# LM3S6965 register map
Vendor: Texas Instruments; File version: 0.1.0
CPU: Cortex-M3 r2p2, little endian, MPU, no FPU, VTOR, 3 interrupt priority bits
Registers are 32-bit, read-write, no defined reset value unless marked. A register's access mark holds for its fields unless they carry their own. Offsets are from the block's base; [hi:lo] are bit positions; {n}, {i} and the like mark numbered series.

## UART0 — Universal asynchronous receiver/transmitter 0.
Base 0x4000C000
Same registers: UART1 0x4000D000
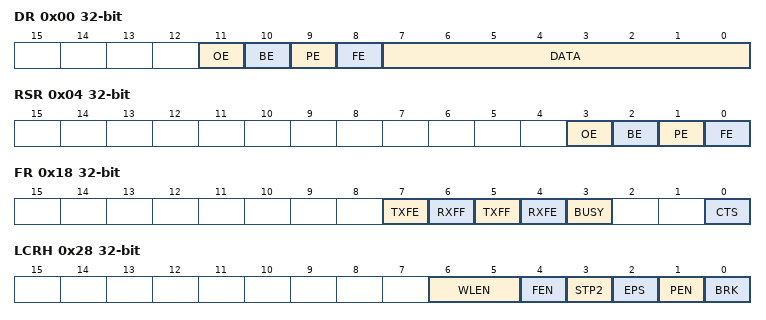
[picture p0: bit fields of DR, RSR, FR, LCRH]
0x00 DR — UART Data
  [11] OE ro — Overrun error.
  [10] BE ro — Break error.
  [9] PE ro — Parity error.
  [8] FE ro — Framing error.
  [7:0] DATA — Transmit/receive data.
0x04 RSR — UART receive status register view.
  [3] OE ro — Overrun error status.
  [2] BE ro — Break error status.
  [1] PE ro — Parity error status.
  [0] FE ro — Framing error status.
0x04 ECR (alternate view of RSR) — UART error clear register view.
  [3:0] ERROR wo — Writing clears receive status errors.
0x18 FR — UART Flag
  [7] TXFE ro — Transmit FIFO empty.
  [6] RXFF ro — Receive FIFO full.
  [5] TXFF ro — Transmit FIFO full.
  [4] RXFE ro — Receive FIFO empty.
  [3] BUSY ro — UART busy transmitting.
  [0] CTS ro — Clear to send state.
0x1C ILPR — UART IrDA Low-Power Register
0x20 IBRD — UART Integer Baud-Rate Divisor
  [15:0] DIVINT — Integer baud divisor.
0x24 FBRD — UART Fractional Baud-Rate Divisor
  [5:0] DIVFRAC — Fractional baud divisor.
0x28 LCRH — UART Line Control
  [6:5] WLEN — Word length.
    {v}={v+5}-bit data (v=0..3)
  [4] FEN — FIFO enable.
  [3] STP2 — Two stop bits.
  [2] EPS — Even parity select.
  [1] PEN — Parity enable.
  [0] BRK — Send break.
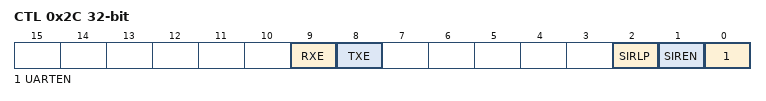
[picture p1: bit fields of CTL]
0x2C CTL — UART Control
  [9] RXE — Receive enable.
  [8] TXE — Transmit enable.
  [2] SIRLP — IrDA low-power mode.
  [1] SIREN — IrDA enable.
  [0] UARTEN — UART enable.
0x30 IFLS — UART Interrupt FIFO Level Select
0x34 IM — UART Interrupt Mask
0x38 RIS — UART Raw Interrupt Status
0x3C MIS — UART Masked Interrupt Status
0x40 ICR wo — UART Interrupt Clear

## I2C0 — Inter-integrated circuit controller 0 with master and slave sub-blocks.
Base 0x40020000
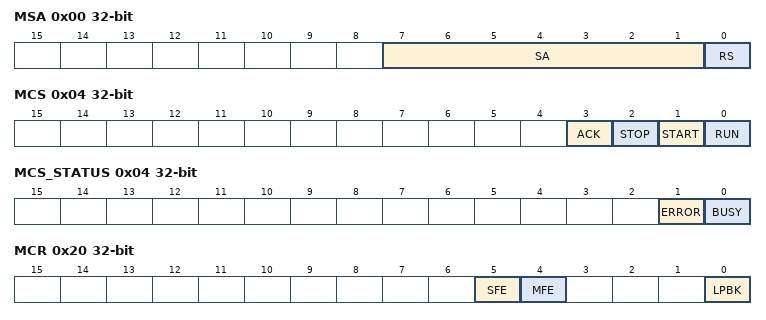
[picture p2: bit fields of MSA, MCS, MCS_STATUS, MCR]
0x00 MSA — I2C Master Slave Address
  [7:1] SA — Target slave address.
  [0] RS — Receive/not-send indicator.
0x04 MCS — I2C Master Control register view.
  [3] ACK — Acknowledge control.
  [2] STOP — Generate STOP condition.
  [1] START — Generate START condition.
  [0] RUN — Start I2C master operation.
0x04 MCS_STATUS (alternate view of MCS) — I2C Master Status register readback view.
  [1] ERROR ro — Error status on readback.
  [0] BUSY ro — Master busy status on readback.
0x08 MDR — I2C Master Data
  [7:0] DATA — Master transmit/receive data.
0x0C MTPR — I2C Master Timer Period
0x10 MIMR — I2C Master Interrupt Mask
0x14 MRIS — I2C Master Raw Interrupt Status
0x18 MMIS — I2C Master Masked Interrupt Status
0x1C MICR wo — I2C Master Interrupt Clear
0x20 MCR — I2C Master Configuration
  [5] SFE — Slave function enable.
  [4] MFE — Master function enable.
  [0] LPBK — Loopback enable.
0x800 SOAR — I2C Slave Own Address
  [6:0] OAR — Slave own address.
0x804 SCSR — I2C Slave Control/Status
0x808 SDR — I2C Slave Data
  [7:0] DATA — Slave data.
0x80C SIMR — I2C Slave Interrupt Mask
0x810 SRIS — I2C Slave Raw Interrupt Status
0x814 SMIS — I2C Slave Masked Interrupt Status
0x818 SICR wo — I2C Slave Interrupt Clear

## TIMER0 — General-purpose timer module 0 with Timer A and Timer B halves.
Base 0x40030000
Same registers: TIMER1 0x40031000, TIMER2 0x40032000, TIMER3 0x40033000
0x00 CFG — GPTM Configuration
  [2:0] CFG — GPTM configuration.
    0=full-32-bit (32-bit timer configuration); 1=rtc (32-bit RTC configuration); 4=split-16-bit (Two 16-bit timers configuration)
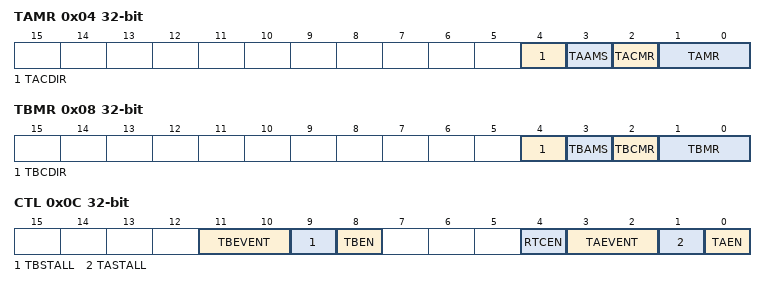
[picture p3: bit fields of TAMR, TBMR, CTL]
0x04 TAMR — GPTM Timer A Mode
  [4] TACDIR — Count direction.
  [3] TAAMS — Alternate mode select for PWM.
  [2] TACMR — Capture mode select.
  [1:0] TAMR — Timer A mode.
    1=One-shot mode; 2=Periodic mode; 3=Capture mode
0x08 TBMR — GPTM Timer B Mode
  [4] TBCDIR — Count direction.
  [3] TBAMS — Alternate mode select for PWM.
  [2] TBCMR — Capture mode select.
  [1:0] TBMR — Timer B mode.
    1=One-shot mode; 2=Periodic mode; 3=Capture mode
0x0C CTL — GPTM Control
  [11:10] TBEVENT — Timer B event selection.
  [9] TBSTALL — Timer B stall in debug.
  [8] TBEN — Timer B enable.
  [4] RTCEN — RTC enable.
  [3:2] TAEVENT — Timer A event selection.
  [1] TASTALL — Timer A stall in debug.
  [0] TAEN — Timer A enable.
0x18 IMR — GPTM Interrupt Mask
0x1C RIS — GPTM Raw Interrupt Status
0x20 MIS — GPTM Masked Interrupt Status
0x24 ICR wo — GPTM Interrupt Clear
0x28 TAILR — GPTM Timer A Interval Load
0x2C TBILR — GPTM Timer B Interval Load
0x30 TAMATCHR — GPTM Timer A Match
0x34 TBMATCHR — GPTM Timer B Match
0x38 TAPR — GPTM Timer A Prescale
0x3C TBPR — GPTM Timer B Prescale
0x40 TAPMR — GPTM TimerA Prescale Match
0x44 TBPMR — GPTM TimerB Prescale Match
0x48 TAR — GPTM Timer A
0x4C TBR — GPTM Timer B

## FLASH_CTRL — Flash memory control block.
Base 0x400FD000
0x00 FMA — Flash Memory Address
0x04 FMD — Flash Memory Data
0x08 FMC — Flash Memory Control
0x0C FCRIS — Flash Controller Raw Interrupt Status
0x10 FCIM — Flash Controller Interrupt Mask
0x14 FCMISC — Flash Controller Masked Interrupt Status and Clear
{0x1200+4i} FMPRE{i} (i=0..3) — Flash Memory Protection Read Enable {i}
{0x1400+4i} FMPPE{i} (i=0..3) — Flash Memory Protection Program Enable {i}

## SYSCTL — System control block for clocks, resets, device capabilities, and reset causes.
Base 0x400FE000
0x00 DID0 — Device Identification 0
0x04 DID1 — Device Identification 1
{0x8+4i} DC{i} (i=0..4) — Device Capabilities {i}
0x2C PBORCTL — Brown-Out Reset Control
0x30 LDOPCTL — LDO Power Control
0x3C SRCR0 — Software Reset Control 0
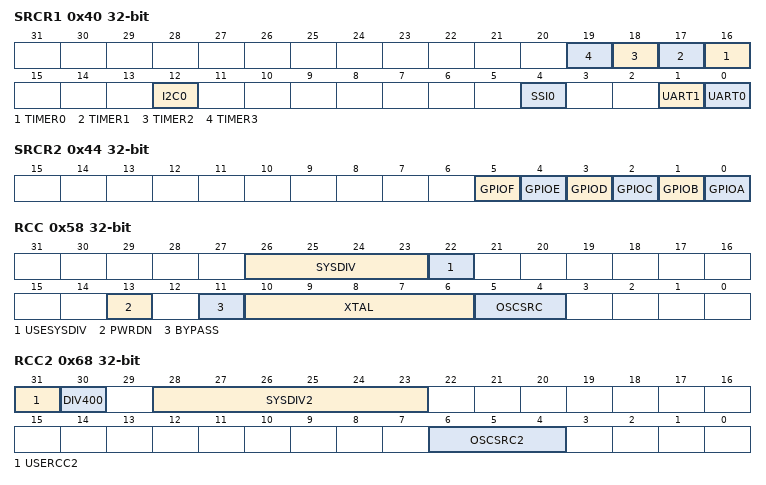
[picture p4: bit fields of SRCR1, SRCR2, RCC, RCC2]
0x40 SRCR1 — Software Reset Control 1
  [n+16] TIMER{n} (n=0..3) — Software reset for Timer {n}.
  [12] I2C0 — Software reset for I2C0.
  [4] SSI0 — Software reset for SSI0.
  [1] UART1 — Software reset for UART1.
  [0] UART0 — Software reset for UART0.
0x44 SRCR2 — Software Reset Control 2
  [5] GPIOF — Software reset for Port F.
  [4] GPIOE — Software reset for Port E.
  [3] GPIOD — Software reset for Port D.
  [2] GPIOC — Software reset for Port C.
  [1] GPIOB — Software reset for Port B.
  [0] GPIOA — Software reset for Port A.
0x48 RIS — Raw Interrupt Status
0x4C IMC — Interrupt Mask Control
0x50 MISC — Masked Interrupt Status and Clear
0x54 RESC — Reset Cause
0x58 RCC — Run-Mode Clock Configuration
  [26:23] SYSDIV — System clock divisor.
  [22] USESYSDIV — Use system divider.
  [13] PWRDN — PLL power down.
  [11] BYPASS — PLL bypass.
  [10:6] XTAL — Crystal value.
  [5:4] OSCSRC — Oscillator source.
0x5C PLLCFG — XTAL to PLL Translation
0x68 RCC2 — Run-Mode Clock Configuration 2
  [31] USERCC2
  [30] DIV400 — Use 400 MHz PLL divisor.
  [28:23] SYSDIV2 — System clock divisor 2.
  [6:4] OSCSRC2 — Oscillator source 2.
0xF8 RCGC0 — Run Mode Clock Gating Control Register 0
  [3] WDT0 — Run-mode clock gate for watchdog 0.
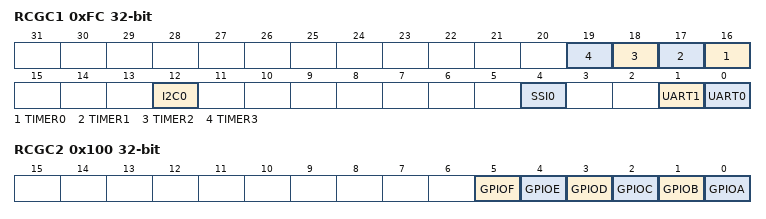
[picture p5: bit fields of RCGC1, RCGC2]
0xFC RCGC1 — Run Mode Clock Gating Control Register 1
  [n+16] TIMER{n} (n=0..3) — Run-mode clock gate for Timer {n}.
  [12] I2C0 — Run-mode clock gate for I2C0.
  [4] SSI0 — Run-mode clock gate for SSI0.
  [1] UART1 — Run-mode clock gate for UART1.
  [0] UART0 — Run-mode clock gate for UART0.
0x100 RCGC2 — Run Mode Clock Gating Control Register 2
  [5] GPIOF — Run-mode clock gate for Port F.
  [4] GPIOE — Run-mode clock gate for Port E.
  [3] GPIOD — Run-mode clock gate for Port D.
  [2] GPIOC — Run-mode clock gate for Port C.
  [1] GPIOB — Run-mode clock gate for Port B.
  [0] GPIOA — Run-mode clock gate for Port A.
{0x104+4i} SCGC{i} (i=0..2) — Sleep Mode Clock Gating Control Register {i}
0x110 DCGC0 — Deep Sleep Mode Clock Gating Control Register 0
0x114 DCGC1 — Deep-Sleep Mode Clock Gating Control Register 1
0x118 DCGC2 — Deep Sleep Mode Clock Gating Control Register 2
0x134 DSLPCLKCFG — Deep Sleep Clock Configuration
